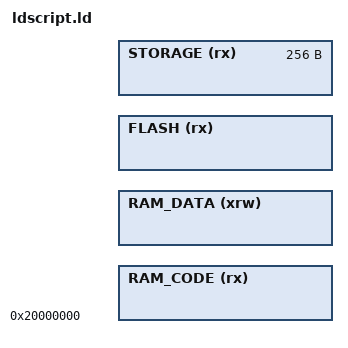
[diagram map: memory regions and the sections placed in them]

/* Linker script for STM32L071xx series 64Kbytes FLASH and 20Kbytes RAM */

/* Page is 128B */
__FLASH_PAGE_SIZE = 128;
__EEPROM_SIZE = 2 * __FLASH_PAGE_SIZE;

/* Specify the memory areas */
MEMORY
{
  RAM_CODE (rx)   : ORIGIN = 0x20000000, LENGTH = DEFINED(RAM_CODE_IGNORE) ? 1K : 8K
  RAM_DATA (xrw)  : ORIGIN = 0x20000000 + LENGTH(RAM_CODE), LENGTH = 20K - LENGTH(RAM_CODE)
  FLASH (rx)      : ORIGIN = 0x8000000 + FLASH_APP_OFFSET, LENGTH = FLASH_SIZE - FLASH_APP_OFFSET - __EEPROM_SIZE
  STORAGE (rx)    : ORIGIN = ORIGIN(FLASH) + LENGTH(FLASH), LENGTH = __EEPROM_SIZE
}

REGION_ALIAS("DMA_DATA", RAM_DATA)
REGION_ALIAS("FLASH_RAM_CODE", FLASH)
REGION_ALIAS("FLASH_STORAGE", STORAGE)

INCLUDE "variants/ldscript_gen.ld"
